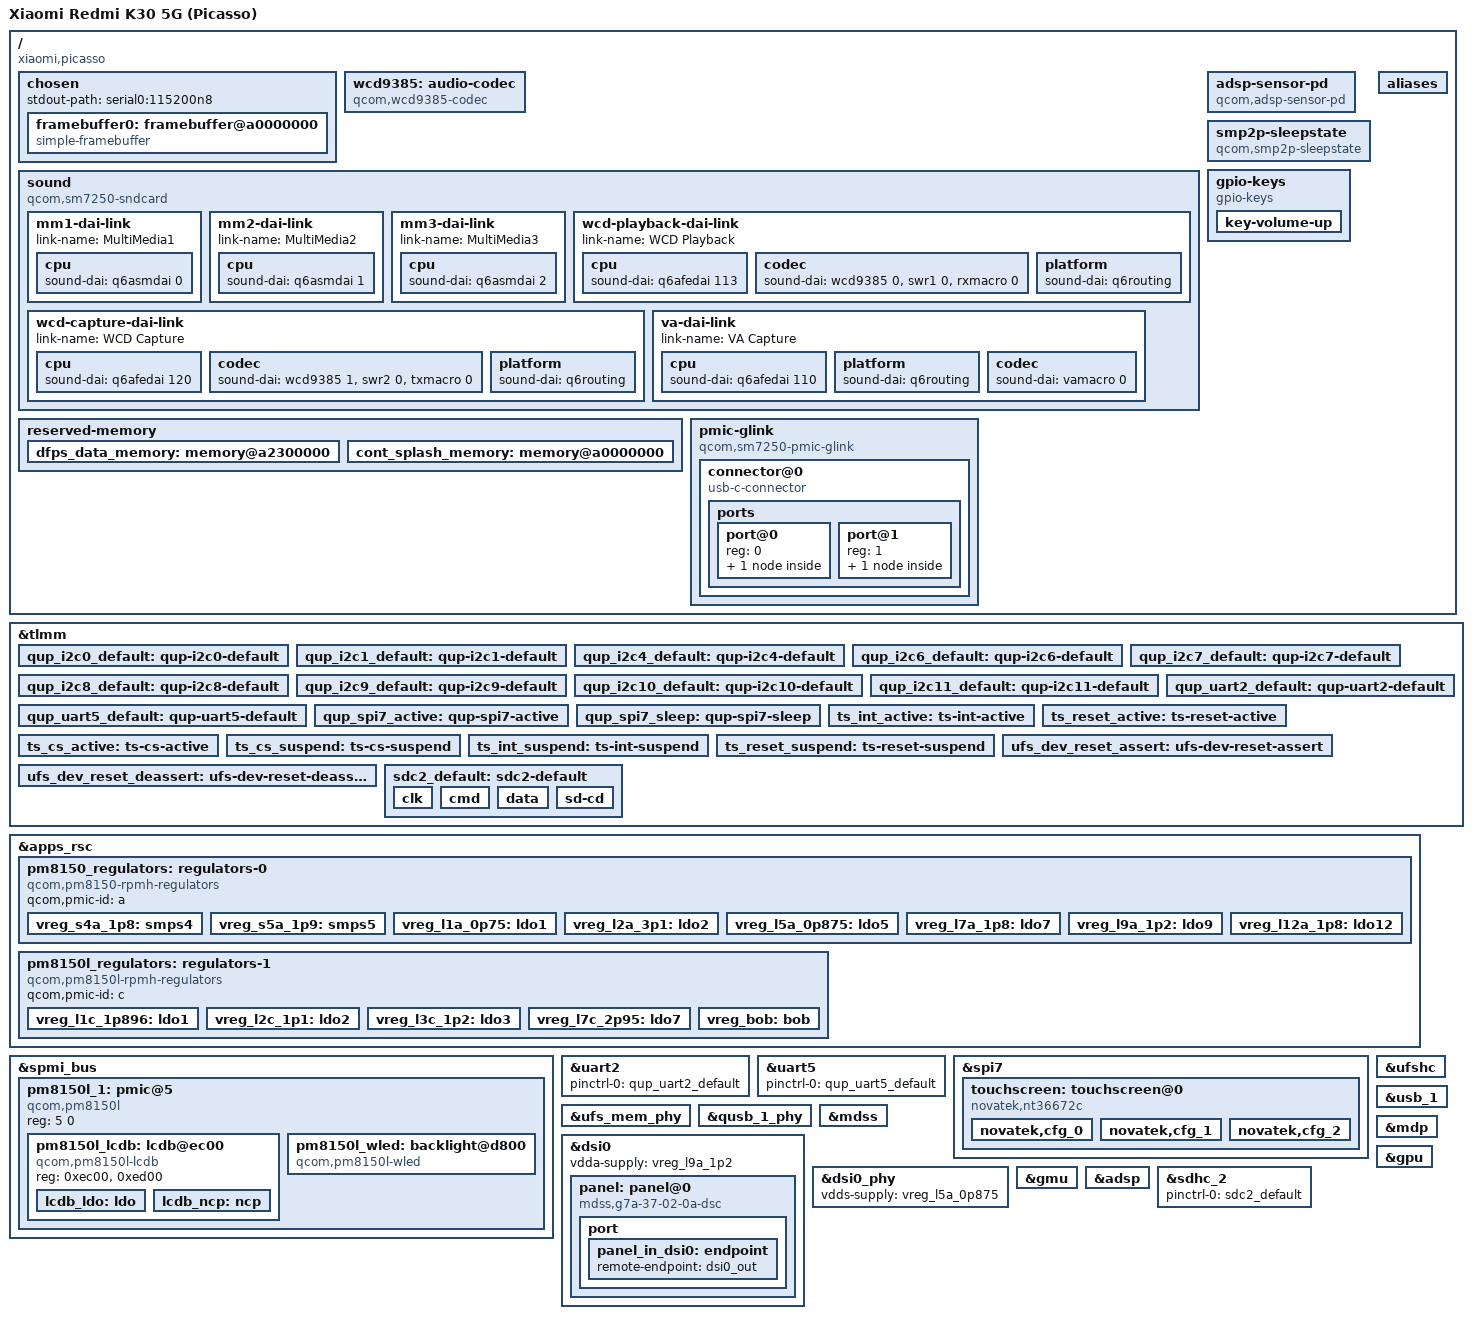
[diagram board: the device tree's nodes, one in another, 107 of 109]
// SPDX-License-Identifier: BSD-3-Clause
/*
 * Xiaomi Redmi K30 5G (picasso) device tree
 *
 * Copyright (c) 2026, Picasso mainline bring-up project
 */

/dts-v1/;

#include "sm7250.dtsi"


/ {
	model = "Xiaomi Redmi K30 5G (Picasso)";
	compatible =
		"xiaomi,picasso",
		"qcom,sm7250",
		"qcom,lito-mtp",
		"qcom,lito",
		"qcom,mtp";
	qcom,msm-id = <0x190 0x10000>;
	qcom,board-id = <36 0>;
	chassis-type = "handset";
	chosen {
		#address-cells = <2>;
		#size-cells = <2>;
		ranges;
		stdout-path = "serial0:115200n8";
		framebuffer0: framebuffer@a0000000 {
			compatible = "simple-framebuffer";
			reg = <0 0xa0000000 0 0x9e3400>;
			width = <0x438>;
			height = <0x960>;
			stride = <0x10e0>;
			format = "a8r8g8b8";
			status = "okay";
		};
	};
	wcd9385: audio-codec {
		compatible = "qcom,wcd9385-codec";
		reset-gpios = <&tlmm 57 1>;
		vdd-buck-supply = <&vreg_s4a_1p8>;
		vdd-rxtx-supply = <&vreg_s4a_1p8>;
		vdd-io-supply = <&vreg_s4a_1p8>;
		vdd-mic-bias-supply = <&vreg_bob>;
		qcom,micbias1-microvolt = <0x29f630>;
		qcom,micbias2-microvolt = <0x29f630>;
		qcom,micbias3-microvolt = <0x29f630>;
		qcom,micbias4-microvolt = <0x29f630>;
		qcom,mbhc-buttons-vthreshold-microvolt =
			<0x124f8 0x249f0 0x39dc8 0x7a120 0x7a120 0x7a120 0x7a120 0x7a120>;
		qcom,mbhc-headset-vthreshold-microvolt = <0x19f0a0>;
		qcom,mbhc-headphone-vthreshold-microvolt = <0xc350>;
		qcom,rx-device = <&wcd9385_rx>;
		qcom,tx-device = <&wcd9385_tx>;
		#sound-dai-cells = <1>;
	};
	sound {
		compatible = "qcom,sm7250-sndcard";
		model = "Xiaomi Redmi K30 5G (Picasso) WCD9385";
		audio-routing =
			"IN1_HPHL",
			"HPHL_OUT",
			"IN2_HPHR",
			"HPHR_OUT",
			"IN3_AUX",
			"AUX_OUT",
			"AMIC1",
			"MIC BIAS1",
			"AMIC2",
			"MIC BIAS2",
			"AMIC5",
			"MIC BIAS3",
			"TX SWR_ADC0",
			"ADC1_OUTPUT",
			"TX SWR_ADC1",
			"ADC2_OUTPUT",
			"TX SWR_ADC2",
			"ADC3_OUTPUT",
			"TX SWR_ADC3",
			"ADC4_OUTPUT",
			"RX_TX DEC0_INP",
			"TX DEC0 MUX",
			"RX_TX DEC1_INP",
			"TX DEC1 MUX",
			"RX_TX DEC2_INP",
			"TX DEC2 MUX",
			"RX_TX DEC3_INP",
			"TX DEC3 MUX",
			"VA_AIF1 CAP",
			"VA_SWR_CLK",
			"VA_AIF2 CAP",
			"VA_SWR_CLK",
			"VA_AIF3 CAP",
			"VA_SWR_CLK",
			"VA DMIC0",
			"MIC BIAS3",
			"VA DMIC1",
			"MIC BIAS3",
			"VA DMIC2",
			"MIC BIAS1",
			"VA DMIC3",
			"MIC BIAS1",
			"VA DMIC4",
			"MIC BIAS4",
			"VA DMIC5",
			"MIC BIAS4",
			"VA SWR_ADC0",
			"ADC1_OUTPUT",
			"VA SWR_ADC1",
			"ADC2_OUTPUT",
			"VA SWR_ADC2",
			"ADC3_OUTPUT",
			"VA SWR_ADC3",
			"ADC4_OUTPUT";
		mm1-dai-link {
			link-name = "MultiMedia1";
			cpu {
				sound-dai = <&q6asmdai 0>;
			};
		};
		mm2-dai-link {
			link-name = "MultiMedia2";
			cpu {
				sound-dai = <&q6asmdai 1>;
			};
		};
		mm3-dai-link {
			link-name = "MultiMedia3";
			cpu {
				sound-dai = <&q6asmdai 2>;
			};
		};
		wcd-playback-dai-link {
			link-name = "WCD Playback";
			cpu {
				sound-dai = <&q6afedai 113>;
			};
			codec {
				sound-dai = <&wcd9385 0 &swr1 0 &rxmacro 0>;
			};
			platform {
				sound-dai = <&q6routing>;
			};
		};
		wcd-capture-dai-link {
			link-name = "WCD Capture";
			cpu {
				sound-dai = <&q6afedai 120>;
			};
			codec {
				sound-dai = <&wcd9385 1 &swr2 0 &txmacro 0>;
			};
			platform {
				sound-dai = <&q6routing>;
			};
		};
		va-dai-link {
			link-name = "VA Capture";
			cpu {
				sound-dai = <&q6afedai 110>;
			};
			platform {
				sound-dai = <&q6routing>;
			};
			codec {
				sound-dai = <&vamacro 0>;
			};
		};
	};
	adsp-sensor-pd {
		compatible = "qcom,adsp-sensor-pd";
		nvmem-cells = <&adsp_variant>;
		nvmem-cell-names = "adsp_variant";
		status = "okay";
	};
	reserved-memory {
		#address-cells = <2>;
		#size-cells = <2>;
		ranges;
		dfps_data_memory: memory@a2300000 {
			reg = <0 0xa2300000 0 0x100000>;
			no-map;
		};
		cont_splash_memory: memory@a0000000 {
			reg = <0 0xa0000000 0 0x2300000>;
			no-map;
		};
	};
	smp2p-sleepstate {
		compatible = "qcom,smp2p-sleepstate";
		qcom,smem-states = <&sleepstate_smp2p_out 0>;
		interrupt-parent = <&sleepstate_smp2p_in>;
		interrupts = <0 0>;
		interrupt-names = "smp2p-sleepstate-in";
	};
	aliases {
		serial0 = "/soc@0/geniqup@8c0000/serial@888000";
		serial1 = "/soc@0/geniqup@8c0000/serial@894000";
	};
	gpio-keys {
		compatible = "gpio-keys";
		key-volume-up {
			label = "Volume Up";
			gpios = <&pm8150l_gpios 5 1>;
			linux,code = <115>;
			debounce-interval = <15>;
			wakeup-source;
		};
	};
	pmic-glink {
		compatible = "qcom,sm7250-pmic-glink", "qcom,pmic-glink";
		#address-cells = <1>;
		#size-cells = <0>;
		connector@0 {
			compatible = "usb-c-connector";
			reg = <0>;
			power-role = "dual";
			data-role = "dual";
			ports {
				#address-cells = <1>;
				#size-cells = <0>;
				port@0 {
					reg = <0>;
					endpoint {
						remote-endpoint =
							<&usb_1_dwc3_ss_out>;
					};
				};
				port@1 {
					reg = <1>;
					endpoint {
						remote-endpoint =
							<&usb_1_dwc3_hs_out>;
					};
				};
			};
		};
	};
};
&tlmm {
	qup_i2c0_default: qup-i2c0-default {
		pins = "gpio42", "gpio43";
		function = "qup00";
		drive-strength = <2>;
		bias-disable;
	};
	qup_i2c1_default: qup-i2c1-default {
		pins = "gpio0", "gpio1";
		function = "qup01";
		drive-strength = <2>;
		bias-disable;
	};
	qup_i2c4_default: qup-i2c4-default {
		pins = "gpio31", "gpio32";
		function = "qup04";
		drive-strength = <2>;
		bias-disable;
	};
	qup_i2c6_default: qup-i2c6-default {
		pins = "gpio59", "gpio60";
		function = "qup10";
		drive-strength = <2>;
		bias-disable;
	};
	qup_i2c7_default: qup-i2c7-default {
		pins = "gpio6", "gpio7";
		function = "qup11";
		drive-strength = <2>;
		bias-disable;
	};
	qup_i2c8_default: qup-i2c8-default {
		pins = "gpio49", "gpio50";
		function = "qup12";
		drive-strength = <2>;
		bias-disable;
	};
	qup_i2c9_default: qup-i2c9-default {
		pins = "gpio46", "gpio47";
		function = "qup13";
		drive-strength = <2>;
		bias-disable;
	};
	qup_i2c10_default: qup-i2c10-default {
		pins = "gpio53", "gpio54";
		function = "qup14";
		drive-strength = <2>;
		bias-disable;
	};
	qup_i2c11_default: qup-i2c11-default {
		pins = "gpio108", "gpio109";
		function = "qup15";
		drive-strength = <2>;
		bias-disable;
	};
	qup_uart2_default: qup-uart2-default {
		pins = "gpio36", "gpio37";
		function = "qup02";
		drive-strength = <2>;
		bias-disable;
	};
	qup_uart5_default: qup-uart5-default {
		pins = "gpio38", "gpio41";
		function = "qup05";
		drive-strength = <2>;
		bias-disable;
	};
	qup_spi7_active: qup-spi7-active {
		/* 触摸 SE7 SPI（live dts qupv3_se7_spi、ts 系列组实测参数） */
		pins = "gpio6", "gpio7", "gpio8";
		function = "qup11";
		drive-strength = <6>;
		bias-disable;
	};
	qup_spi7_sleep: qup-spi7-sleep {
		pins = "gpio6", "gpio7", "gpio8";
		function = "gpio";
		drive-strength = <6>;
		bias-disable;
	};
	ts_int_active: ts-int-active {
		pins = "gpio5";
		function = "gpio";
		drive-strength = <16>;
		bias-pull-down;
	};
	ts_reset_active: ts-reset-active {
		pins = "gpio4";
		function = "gpio";
		drive-strength = <16>;
		bias-pull-up;
	};
	ts_cs_active: ts-cs-active {
		pins = "gpio9";
		function = "qup11";
		drive-strength = <6>;
		bias-disable;
	};
	ts_cs_suspend: ts-cs-suspend {
		pins = "gpio9";
		function = "gpio";
		drive-strength = <6>;
		bias-pull-down;
		output-low;
	};
	ts_int_suspend: ts-int-suspend {
		pins = "gpio5";
		function = "gpio";
		drive-strength = <16>;
		bias-disable;
		input-enable;
	};
	ts_reset_suspend: ts-reset-suspend {
		pins = "gpio4";
		function = "gpio";
		drive-strength = <16>;
		bias-disable;
	};
	ufs_dev_reset_assert: ufs-dev-reset-assert {
		/* UFS 设备复位：TLMM 专用 ufs_reset 组（pin 146，非 gpio
					 * 范围，gpiod 够不着）——ufs-qcom 走 pinctrl 两态
					 * （迭代 32）。参数照 live_dts 实值（bias-pull-down +
					 * drive 8 + output 电平），无 function（mux_bit=-1 的
					 * 特殊组只走 config）。注：7.3 的 generic pinconf 把
					 * output-high/low 解析为 PIN_CONFIG_LEVEL，pinctrl-msm
					 * 原生支持该路径（io_reg 写电平）——无需框架改动 */
		pins = "ufs_reset";
		drive-strength = <8>;
		bias-pull-down;
		output-low;
	};
	ufs_dev_reset_deassert: ufs-dev-reset-deassert {
		pins = "ufs_reset";
		drive-strength = <8>;
		bias-pull-down;
		output-high;
	};
	sdc2_default: sdc2-default {
		clk {
			pins = "sdc2_clk";
			drive-strength = <16>;
			bias-disable;
		};
		cmd {
			pins = "sdc2_cmd";
			drive-strength = <10>;
			bias-pull-up;
		};
		data {
			pins = "sdc2_data";
			drive-strength = <10>;
			bias-pull-up;
		};
		sd-cd {
			pins = "gpio69";
			drive-strength = <2>;
			bias-pull-up;
		};
	};
};
&apps_rsc {
	pm8150_regulators: regulators-0 {
		compatible = "qcom,pm8150-rpmh-regulators";
		qcom,pmic-id = "a";
		vreg_s4a_1p8: smps4 {
			regulator-name = "vreg_s4a_1p8";
			regulator-min-microvolt = <0x1b7740>;
			regulator-max-microvolt = <0x1b7740>;
			regulator-initial-mode = <3>;
		};
		vreg_s5a_1p9: smps5 {
			regulator-name = "vreg_s5a_1p9";
			regulator-min-microvolt = <0x1d0d80>;
			regulator-max-microvolt = <0x1f20c0>;
			regulator-initial-mode = <3>;
		};
		vreg_l1a_0p75: ldo1 {
			/* ldoa1 = pmic5_nldo（0.312-1.328V），保持原值（无消费者）。
							   注意：下游运行时树里名叫 "pm8150a_l1" 的 1.896V 面板 vddio
							   实际挂在 ldoc1（其父块是 rpmh-regulator-ldoc1，小米 R 的
							   命名误导）——见 regulators-1 的 ldo1 */
			regulator-name = "vreg_l1a_0p75";
			regulator-min-microvolt = <0xb7980>;
			regulator-max-microvolt = <0xb7980>;
			regulator-initial-mode = <1>;
		};
		vreg_l2a_3p1: ldo2 {
			regulator-name = "vreg_l2a_3p1";
			regulator-min-microvolt = <0x2ee000>;
			regulator-max-microvolt = <0x2ee000>;
			regulator-initial-mode = <1>;
		};
		vreg_l5a_0p875: ldo5 {
			regulator-name = "vreg_l5a_0p875";
			regulator-min-microvolt = <0xd6d80>;
			regulator-max-microvolt = <0xd6d80>;
			/* P41: UFS/DSI analog supply stays in HPM. */
			regulator-initial-mode = <3>;
			regulator-allow-set-load;
			regulator-allowed-modes = <3>;
		};
		vreg_l7a_1p8: ldo7 {
			regulator-name = "vreg_l7a_1p8";
			regulator-min-microvolt = <0x1b7740>;
			regulator-max-microvolt = <0x1b7740>;
			regulator-initial-mode = <1>;
		};
		vreg_l9a_1p2: ldo9 {
			regulator-name = "vreg_l9a_1p2";
			regulator-min-microvolt = <0x124f80>;
			regulator-max-microvolt = <0x124f80>;
			/* 19mA UFS load is below the 30mA HPM threshold. */
			regulator-initial-mode = <3>;
			regulator-allow-set-load;
			regulator-allowed-modes = <3>;
		};
		vreg_l12a_1p8: ldo12 {
			regulator-name = "vreg_l12a_1p8";
			regulator-min-microvolt = <0x1b7740>;
			regulator-max-microvolt = <0x1b7740>;
			regulator-initial-mode = <1>;
		};
	};
	pm8150l_regulators: regulators-1 {
		/* lito 固件里 PM8150L 的 cmd-db 资源前缀是 "c"（ldoc1-11/smpc2,7,8/bobc1），
						   不是 kona 的 "l"；用 "l" 会在 cmd_db_read_addr("ldol1") 处 -ENODEV */
		compatible = "qcom,pm8150l-rpmh-regulators";
		qcom,pmic-id = "c";
		vreg_l1c_1p896: ldo1 {
			/* 面板 vddio：实为 PM8150L ldoc1 @1.896V（pldo_lv
							   1.504-2.0V@8mV 可精确命中；下游 picasso &L1C 同值） */
			regulator-name = "vreg_l1c_1p896";
			regulator-min-microvolt = <0x1cee40>;
			regulator-max-microvolt = <0x1cee40>;
			regulator-initial-mode = <3>;
		};
		vreg_l2c_1p1: ldo2 {
			/* ldoc2 = pmic5_nldo（上限 1.328V），旧 3.008V 超范围导致
							   regs-1 整组 -131。改回范围内值（无消费者） */
			regulator-name = "vreg_l2c_1p1";
			regulator-min-microvolt = <0x1174c0>;
			regulator-max-microvolt = <0x1174c0>;
			regulator-initial-mode = <1>;
		};
		vreg_l3c_1p2: ldo3 {
			regulator-name = "vreg_l3c_1p2";
			regulator-min-microvolt = <0x124f80>;
			regulator-max-microvolt = <0x124f80>;
			regulator-initial-mode = <1>;
		};
		vreg_l7c_2p95: ldo7 {
			regulator-name = "vreg_l7c_2p95";
			regulator-min-microvolt = <0x2d0370>;
			regulator-max-microvolt = <0x2d2a80>;
			/* UFS VCC: enable load voting and keep HPM. */
			regulator-initial-mode = <3>;
			regulator-allow-set-load;
			regulator-allowed-modes = <3>;
		};
		vreg_bob: bob {
			/* live_dts bobc1: 3.008..3.96V；WCD9385 mic-bias 供轨 */
			regulator-name = "vreg_bob";
			regulator-min-microvolt = <0x2de600>;
			regulator-max-microvolt = <0x3c6cc0>;
			regulator-initial-mode = <3>;
		};
	};
};
&spmi_bus {
	pm8150l_1: pmic@5 {
		/* 下游 pm8150l.dtsi：WLED/LCDB 在 USID 5（SPMI 外设按 USID
					   寻址，放错 USID 写入无响应） */
		compatible = "qcom,pm8150l", "qcom,spmi-pmic";
		reg = <5 0>;
		#address-cells = <1>;
		#size-cells = <0>;
		pm8150l_lcdb: lcdb@ec00 {
			compatible = "qcom,pm8150l-lcdb";
			/* SPMI 孙节点 #size-cells=0：reg 为地址段列表；
								   驱动用第 0 段（0xec00），第二段预留（主线 wled 模式） */
			reg = <0xec00>, <0xed00>;
			lcdb_ldo: ldo {
				/* 面板 avdd（正 bias） */
				regulator-name = "lcdb_ldo";
				regulator-min-microvolt = <0x53ec60>;
				regulator-max-microvolt = <0x53ec60>;
			};
			lcdb_ncp: ncp {
				/* 面板 avee（负 bias） */
				regulator-name = "lcdb_ncp";
				regulator-min-microvolt = <0x53ec60>;
				regulator-max-microvolt = <0x53ec60>;
			};
		};
		pm8150l_wled: backlight@d800 {
			compatible = "qcom,pm8150l-wled";
			/* 主线 pm8150l.dtsi 惯例：ctrl + sink 两段 */
			reg = <0xd800>, <0xd900>;
			qcom,enabled-strings = <0 1 2>;
			qcom,cabc;
			default-brightness = <0x800>;
			max-brightness = <0xfff>;
		};
	};
};
&uart2 {
	pinctrl-names = "default";
	pinctrl-0 = <&qup_uart2_default>;
	status = "okay";
};
&uart5 {
	pinctrl-names = "default";
	pinctrl-0 = <&qup_uart5_default>;
};
&spi7 {
	pinctrl-names = "default", "sleep";
	pinctrl-0 = <&qup_spi7_active>;
	pinctrl-1 = <&qup_spi7_sleep>;
	status = "okay";
	touchscreen: touchscreen@0 {
		compatible = "novatek,nt36672c";
		reg = <0>;
		spi-max-frequency = <0x4c4b40>;
		reset-gpios = <&tlmm 4 0>;
		irq-gpios = <&tlmm 5 0>;
		pinctrl-names = "pmx_ts_active", "pmx_ts_suspend";
		pinctrl-0 = <&ts_int_active &ts_reset_active &ts_cs_active>;
		pinctrl-1 = <&ts_int_suspend &ts_reset_suspend &ts_cs_suspend>;
		novatek,swrst-n8-addr = <0x3f0fe>;
		novatek,spi-rd-fast-addr = <0x3f310>;
		novatek,config-array-size = <3>;
		novatek,cfg_0 {
			novatek,tp-vendor = <65>;
			novatek,display-maker = <55>;
			novatek,glass-vendor = <0>;
			novatek,fw-name = "novatek_nt36672c_g7a_fw01.bin";
			novatek,mp-name = "novatek_nt36672c_g7a_mp01.bin";
		};
		novatek,cfg_1 {
			novatek,tp-vendor = <65>;
			novatek,display-maker = <55>;
			novatek,glass-vendor = <1>;
			novatek,fw-name = "novatek_nt36672c_g7a_fw02.bin";
			novatek,mp-name = "novatek_nt36672c_g7a_mp02.bin";
		};
		novatek,cfg_2 {
			novatek,tp-vendor = <70>;
			novatek,display-maker = <54>;
			novatek,glass-vendor = <0>;
			novatek,fw-name = "novatek_nt36672c_g7a_fw03.bin";
			novatek,mp-name = "novatek_nt36672c_g7a_mp03.bin";
		};
	};
};
&ufshc {
	/*
	 * The UFS device reset line is driven by the dedicated UFS reset
	 * pinctrl group; ufs-qcom selects these states by name when no
	 * reset GPIO is described.
	 */
	pinctrl-names = "dev-reset-assert", "dev-reset-deassert";
	pinctrl-0 = <&ufs_dev_reset_assert>;
	pinctrl-1 = <&ufs_dev_reset_deassert>;
	vcc-supply = <&vreg_l7c_2p95>;
	vcc-max-microamp = <800000>;
	vccq2-supply = <&vreg_s4a_1p8>;
	vccq2-max-microamp = <800000>;
	status = "okay";
};
&ufs_mem_phy {
	vdda-phy-supply = <&vreg_l5a_0p875>;
	vdda-pll-supply = <&vreg_l9a_1p2>;
	status = "okay";
};
&usb_1 {
	status = "okay";
};
&qusb_1_phy {
	vdda-pll-supply = <&vreg_l5a_0p875>;
	vdda33-supply = <&vreg_l2a_3p1>;
	vdda18-supply = <&vreg_l12a_1p8>;
	status = "okay";
};
&mdss {
	status = "okay";
};
&mdp {
	status = "okay";
};
&dsi0 {
	vdda-supply = <&vreg_l9a_1p2>;
	status = "okay";
	panel: panel@0 {
		compatible = "mdss,g7a-37-02-0a-dsc";
		reg = <0>;
		backlight = <&pm8150l_wled>;
		reset-gpios = <&pm8150l_gpios 3 1>;
		/* 面板供电：vddio=ldoc1 1.896V(0x106，下游 "pm8150a_l1"
							   实挂 ldoc1)，avdd/avee=LCDB ldo/ncp(0x103/0x104) */
		vddio-supply = <&vreg_l1c_1p896>;
		avdd-supply = <&lcdb_ldo>;
		avee-supply = <&lcdb_ncp>;
		port {
			panel_in_dsi0: endpoint {
				remote-endpoint = <&dsi0_out>;
			};
		};
	};
};
&dsi0_phy {
	vdds-supply = <&vreg_l5a_0p875>;
	status = "okay";
};
&gpu {
	status = "okay";
};
&gmu {
	status = "okay";
};
&adsp {
	status = "okay";
};
&sdhc_2 {
	pinctrl-names = "default";
	pinctrl-0 = <&sdc2_default>;
};
